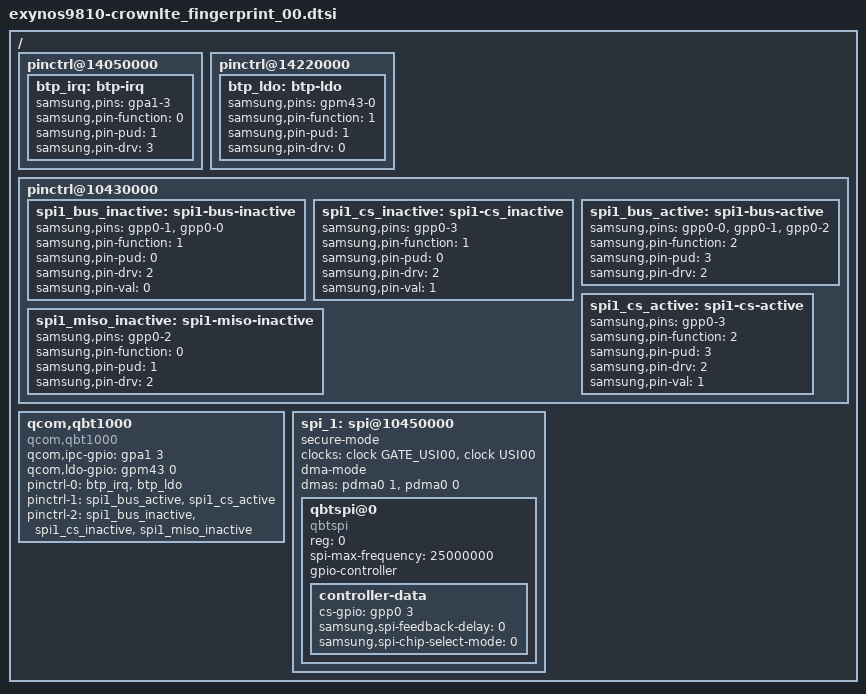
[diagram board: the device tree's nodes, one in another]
/*
 * Copyright (c) 2012-2013, The Linux Foundation. All rights reserved.
 *
 * This program is free software; you can redistribute it and/or modify
 * it under the terms of the GNU General Public License version 2 and
 * only version 2 as published by the Free Software Foundation.
 *
 * This program is distributed in the hope that it will be useful,
 * but WITHOUT ANY WARRANTY; without even the implied warranty of
 * MERCHANTABILITY or FITNESS FOR A PARTICULAR PURPOSE.  See the
 * GNU General Public License for more details.
 */

/ {
	pinctrl@14050000 {
		btp_irq: btp-irq {
			samsung,pins = "gpa1-3";
			samsung,pin-function = <0>;
			samsung,pin-pud = <1>;
			samsung,pin-drv = <3>;
		};
	};

	pinctrl@14220000 {
		btp_ldo: btp-ldo {
			samsung,pins = "gpm43-0";
			samsung,pin-function = <1>;
			samsung,pin-pud = <1>;
			samsung,pin-drv = <0>;
		};
	};

	pinctrl@10430000 {
		/* SPI_FP */
		spi1_bus_inactive: spi1-bus-inactive {
			samsung,pins = "gpp0-1", "gpp0-0";
			samsung,pin-function = <1>;
			samsung,pin-pud = <0>;
			samsung,pin-drv = <2>;
			samsung,pin-val = <0>;
		};
		spi1_cs_inactive: spi1-cs_inactive {
			samsung,pins = "gpp0-3";
			samsung,pin-function = <1>;
			samsung,pin-pud = <0>;
			samsung,pin-drv = <2>;
			samsung,pin-val = <1>;
		};
		spi1_miso_inactive: spi1-miso-inactive {
			samsung,pins = "gpp0-2";
			samsung,pin-function = <0>;
			samsung,pin-pud = <1>;
			samsung,pin-drv = <2>;
		};
		spi1_bus_active: spi1-bus-active {
			samsung,pins = "gpp0-0", "gpp0-1", "gpp0-2";
			samsung,pin-function = <2>;
			samsung,pin-pud = <3>;
			samsung,pin-drv = <2>;
		};
		spi1_cs_active: spi1-cs-active {
			samsung,pins = "gpp0-3";
			samsung,pin-function = <2>;
			samsung,pin-pud = <3>;
			samsung,pin-drv = <2>;
			samsung,pin-val = <1>;
		};
	};

	qcom,qbt1000 {
		compatible = "qcom,qbt1000";
		qcom,ipc-gpio = <&gpa1 3 0x00>;
		qcom,ldo-gpio = <&gpm43 0 0x00>;

		pinctrl-names = "default", "idle", "sleep";
		pinctrl-0 = <&btp_irq &btp_ldo>;
		pinctrl-1 = <&spi1_bus_active &spi1_cs_active>;
		pinctrl-2 = <&spi1_bus_inactive &spi1_cs_inactive &spi1_miso_inactive>;
	};

	/* SPI USI_PERIC0_USI00_SPI */
	spi_1: spi@10450000 {
		status = "okay";
		secure-mode;
		#address-cells = <1>;
		#size-cells = <0>;
		clocks = <&clock GATE_USI00>, <&clock USI00>;
		clock-names = "spi", "spi_busclk0";

		dma-mode;
		dmas = <&pdma0 1 &pdma0 0>;
		/delete-property/ swap-mode;

		/delete-property/ pinctrl-names;
		/delete-property/ pinctrl-0;
		/delete-property/ pinctrl-1;

		qbtspi@0 {
			compatible = "qbtspi";
			reg = <0>;
			spi-max-frequency = <25000000>;

			gpio-controller;
			#gpio-cells = <2>;
			
			controller-data {
				cs-gpio = <&gpp0 3 0>;
				samsung,spi-feedback-delay = <0>;
				samsung,spi-chip-select-mode = <0>;
			};
		};
	};
};
